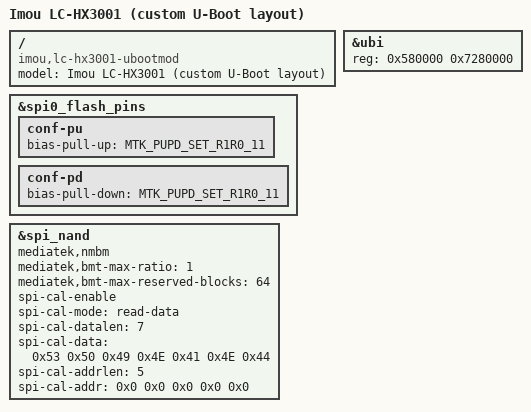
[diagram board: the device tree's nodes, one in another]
// SPDX-License-Identifier: GPL-2.0-or-later OR MIT

/dts-v1/;
#include "mt7981b-imou-lc-hx3001.dts"

/ {
	model = "Imou LC-HX3001 (custom U-Boot layout)";
	compatible = "imou,lc-hx3001-ubootmod", "mediatek,mt7981";
};

&spi0_flash_pins {
	conf-pu {
		/delete-property/ mediatek,pull-up-adv;
		bias-pull-up = <MTK_PUPD_SET_R1R0_11>;
	};

	conf-pd {
		/delete-property/ mediatek,pull-up-adv;
		bias-pull-down = <MTK_PUPD_SET_R1R0_11>;
	};
};

&spi_nand {
	mediatek,nmbm;
	mediatek,bmt-max-ratio = <1>;
	mediatek,bmt-max-reserved-blocks = <64>;

	spi-cal-enable;
	spi-cal-mode = "read-data";
	spi-cal-datalen = <7>;
	spi-cal-data = /bits/ 8 <0x53 0x50 0x49 0x4E 0x41 0x4E 0x44>;
	spi-cal-addrlen = <5>;
	spi-cal-addr = /bits/ 32 <0x0 0x0 0x0 0x0 0x0>;
};

&ubi {
	reg = <0x580000 0x7280000>;
};
